# STM32H7P4xx register map
File version: 1.0
Registers are 32-bit, read-write, reset 0x0 unless marked. A register's access mark holds for its fields unless they carry their own. Offsets are from the block's base; [hi:lo] are bit positions; {n}, {i} and the like mark numbered series; 'fields as' and 'values as' point back to an identical list.

## RCC — Reset and clock control (RCC)
Base 0x58024400
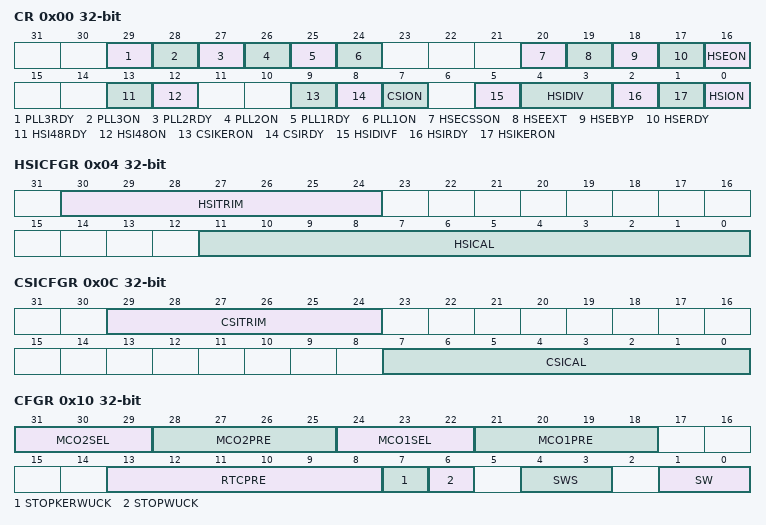
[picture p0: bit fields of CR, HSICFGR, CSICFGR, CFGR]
0x00 CR — RCC source control register
  [29] PLL3RDY — PLL3 clock ready flag
  [28] PLL3ON — PLL3 enable
  [27] PLL2RDY — PLL2 clock ready flag
  [26] PLL2ON — PLL2 enable
  [25] PLL1RDY — PLL1 clock ready flag
  [24] PLL1ON — PLL1 enable
  [20] HSECSSON
  [19] HSEEXT
  [18] HSEBYP — HSE clock bypass
  [17] HSERDY — HSE clock ready flag
  [16] HSEON — HSE clock enable
  [13] HSI48RDY — HSI48 clock ready flag
  [12] HSI48ON — HSI48 clock enable
  [9] CSIKERON — CSI clock enable in Stop mode
  [8] CSIRDY — CSI clock ready flag
  [7] CSION — CSI clock enable
  [5] HSIDIVF — HSI divider flag
  [4:3] HSIDIV — HSI clock divider
  [2] HSIRDY — HSI clock ready flag
  [1] HSIKERON — HSI clock enable in Stop mode
  [0] HSION — HSI clock enable
0x04 HSICFGR — RCC HSI calibration register
  [30:24] HSITRIM — HSI clock trimming
  [11:0] HSICAL — HSI clock calibration
0x08 CRRCR ro — RCC clock recovery RC register
  [9:0] HSI48CAL
0x0C CSICFGR — RCC CSI calibration register
  [29:24] CSITRIM — CSI clock trimming
  [7:0] CSICAL — CSI clock calibration
0x10 CFGR — RCC clock configuration register
  [31:29] MCO2SEL
  [28:25] MCO2PRE — MCO2 prescaler
  [24:22] MCO1SEL
  [21:18] MCO1PRE — MCO1 prescaler
  [13:8] RTCPRE
  [7] STOPKERWUCK
  [6] STOPWUCK
  [4:3] SWS — system clock switch status
  [1:0] SW — system clock switch
0x18 CDCFGR — RCC CPU domain clock configuration register
  [3:0] CPRE — CPU domain core prescaler
0x1C BMCFGR — RCC AHB clock configuration register
  [3:0] BMPRE — Bus matrix clock prescaler
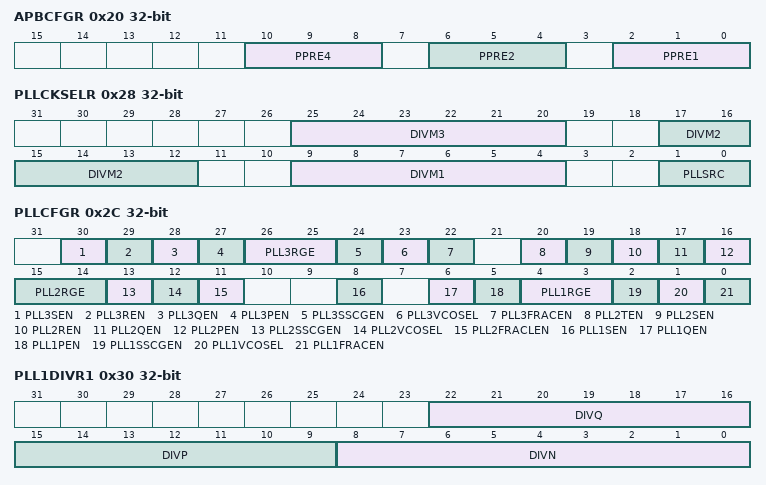
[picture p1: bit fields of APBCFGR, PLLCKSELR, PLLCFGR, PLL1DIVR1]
0x20 APBCFGR — RCC APB clocks configuration register
  [10:8] PPRE4 — CPU domain APB4 prescaler
  [6:4] PPRE2 — CPU domain APB2 prescaler
  [2:0] PPRE1 — CPU domain APB1 prescaler
0x28 PLLCKSELR — RCC PLLs clock source selection register
  [25:20] DIVM3 — prescaler for PLL3
  [17:12] DIVM2 — prescaler for PLL2
  [9:4] DIVM1 — prescaler for PLL1
  [1:0] PLLSRC
0x2C PLLCFGR — RCC PLLs configuration register
  [30] PLL3SEN
  [29] PLL3REN
  [28] PLL3QEN
  [27] PLL3PEN
  [26:25] PLL3RGE — PLL3 input frequency range
  [24] PLL3SSCGEN — PLL3 SSCG enable
  [23] PLL3VCOSEL — PLL3 VCO selection
  [22] PLL3FRACEN — PLL3 fractional latch enable
  [20] PLL2TEN
  [19] PLL2SEN
  [18] PLL2REN
  [17] PLL2QEN
  [16] PLL2PEN
  [15:14] PLL2RGE — PLL2 input frequency range
  [13] PLL2SSCGEN — PLL2 SSCG enable
  [12] PLL2VCOSEL — PLL2 VCO selection
  [11] PLL2FRACLEN — PLL2 fractional latch enable
  [8] PLL1SEN
  [6] PLL1QEN
  [5] PLL1PEN
  [4:3] PLL1RGE — PLL1 input frequency range
  [2] PLL1SSCGEN — PLL1 SSCG enable
  [1] PLL1VCOSEL — PLL1 VCO selection
  [0] PLL1FRACEN — PLL1 fractional latch enable
0x30 PLL1DIVR1 — RCC PLL1 dividers configuration register 1
  [22:16] DIVQ — PLL1 DIVQ division factor
  [15:9] DIVP — PLL1 DIVP division factor
  [8:0] DIVN
{0x2C+8i} PLL{i}FRACR (i=1..3) — RCC PLL{i} fractional divider register
  [15:3] FRACN
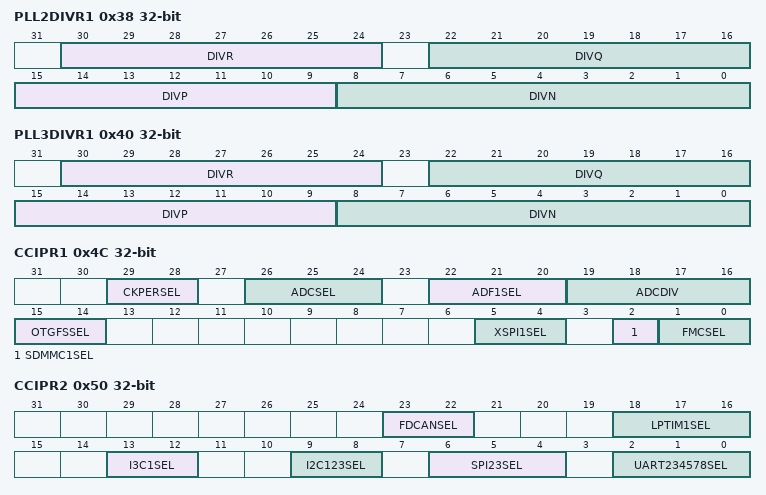
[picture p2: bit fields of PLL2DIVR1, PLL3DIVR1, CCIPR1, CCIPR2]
0x38 PLL2DIVR1 — RCC PLL2 dividers configuration register 1
  [30:24] DIVR — PLL2 DIVR division factor
  [22:16] DIVQ — PLL2 DIVQ division factor
  [15:9] DIVP — PLL2 DIVP division factor
  [8:0] DIVN
0x40 PLL3DIVR1 — RCC PLL3 dividers configuration register 1
  [30:24] DIVR — PLL3 DIVR division factor
  [22:16] DIVQ — PLL3 DIVQ division factor
  [15:9] DIVP — PLL3 DIVP division factor
  [8:0] DIVN
0x4C CCIPR1 — RCC peripheral kernel clock selection register 1
  [29:28] CKPERSEL — per_ck clock source selection
  [26:24] ADCSEL
  [22:20] ADF1SEL
  [19:16] ADCDIV
  [15:14] OTGFSSEL
  [5:4] XSPI1SEL
  [2] SDMMC1SEL
  [1:0] FMCSEL
0x50 CCIPR2 — RCC peripheral kernel clock selection register 2
  [23:22] FDCANSEL, [18:16] LPTIM1SEL, [13:12] I3C1SEL, [9:8] I2C123SEL, [6:4] SPI23SEL, [2:0] UART234578SEL
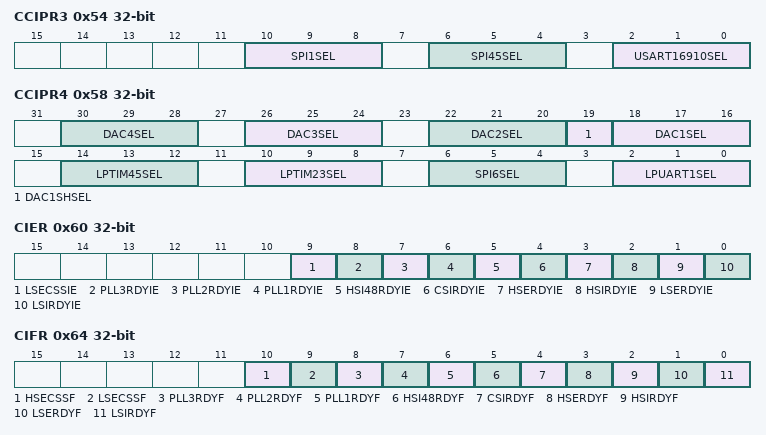
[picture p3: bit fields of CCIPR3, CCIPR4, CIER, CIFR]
0x54 CCIPR3 — RCC peripheral kernel clock selection register 3
  [10:8] SPI1SEL, [6:4] SPI45SEL, [2:0] USART16910SEL
0x58 CCIPR4 — RCC peripheral kernel clock selection register 4
  [4n+14:4n+12] DAC{n}SEL (n=1..4)
  [19] DAC1SHSEL — DAC1 hold clock selection
  [14:12] LPTIM45SEL
  [10:8] LPTIM23SEL
  [6:4] SPI6SEL
  [2:0] LPUART1SEL
0x60 CIER — RCC clock source interrupt enable register
  [9] LSECSSIE
  [8] PLL3RDYIE — PLL3 ready interrupt enable
  [7] PLL2RDYIE — PLL2 ready interrupt enable
  [6] PLL1RDYIE — PLL1 ready interrupt enable
  [5] HSI48RDYIE — HSI48 ready interrupt enable
  [4] CSIRDYIE — CSI ready interrupt enable
  [3] HSERDYIE — HSE ready interrupt enable
  [2] HSIRDYIE — HSI ready interrupt enable
  [1] LSERDYIE — LSE ready interrupt enable
  [0] LSIRDYIE — LSI ready interrupt enable
0x64 CIFR ro — RCC clock source interrupt flag register
  [10] HSECSSF
  [9] LSECSSF
  [8] PLL3RDYF — PLL3 ready interrupt flag
  [7] PLL2RDYF — PLL2 ready interrupt flag
  [6] PLL1RDYF — PLL1 ready interrupt flag
  [5] HSI48RDYF — HSI48 ready interrupt flag
  [4] CSIRDYF — CSI ready interrupt flag
  [3] HSERDYF — HSE ready interrupt flag
  [2] HSIRDYF — HSI ready interrupt flag
  [1] LSERDYF — LSE ready interrupt flag
  [0] LSIRDYF — LSI ready interrupt flag
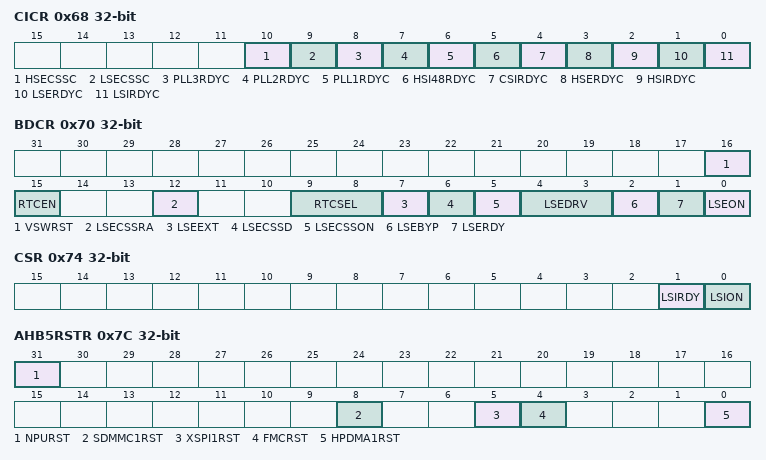
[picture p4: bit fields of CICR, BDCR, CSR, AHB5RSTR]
0x68 CICR — RCC clock source interrupt clear register
  [10] HSECSSC
  [9] LSECSSC
  [8] PLL3RDYC — PLL3 ready interrupt clear
  [7] PLL2RDYC — PLL2 ready interrupt clear
  [6] PLL1RDYC — PLL1 ready interrupt clear
  [5] HSI48RDYC — HSI48 ready interrupt clear
  [4] CSIRDYC — CSI ready interrupt clear
  [3] HSERDYC — HSE ready interrupt clear
  [2] HSIRDYC — HSI ready interrupt clear
  [1] LSERDYC — LSE ready interrupt clear
  [0] LSIRDYC — LSI ready interrupt clear
0x70 BDCR — RCC Backup domain control register
  [16] VSWRST — VSwitch domain software reset
  [15] RTCEN — RTC clock enable
  [12] LSECSSRA — Re-Arm the LSECSS function
  [9:8] RTCSEL — RTC clock source selection
  [7] LSEEXT
  [6] LSECSSD
  [5] LSECSSON
  [4:3] LSEDRV
  [2] LSEBYP — LSE oscillator bypass
  [1] LSERDY — LSE oscillator ready
  [0] LSEON — LSE oscillator enabled
0x74 CSR — RCC clock control and status register
  [1] LSIRDY — LSI oscillator ready
  [0] LSION — LSI oscillator enable
0x7C AHB5RSTR — RCC AHB5 peripheral reset register
  [31] NPURST — NPU block reset
  [8] SDMMC1RST
  [5] XSPI1RST — XSPI1 and MCE1 blocks reset
  [4] FMCRST — FMC and MCE3 blocks reset
  [0] HPDMA1RST — HPDMA1 block reset
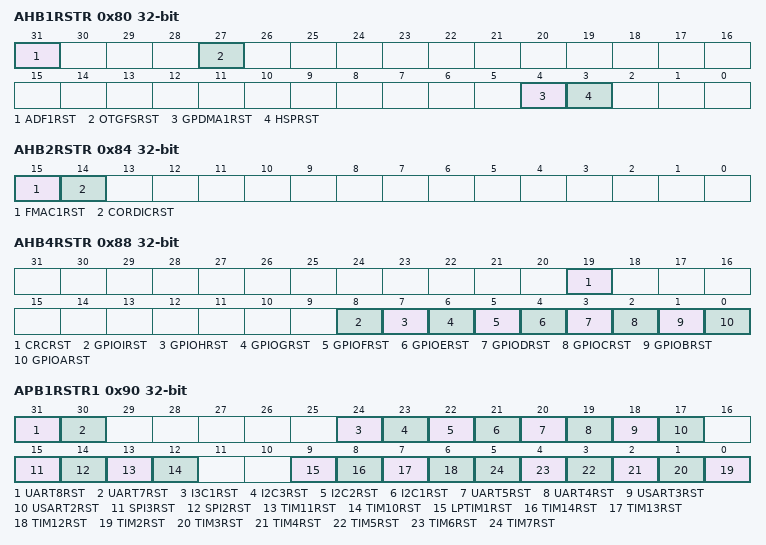
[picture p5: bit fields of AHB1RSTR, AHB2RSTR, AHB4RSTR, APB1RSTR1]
0x80 AHB1RSTR — RCC AHB1 peripheral reset register
  [31] ADF1RST — ADF block reset
  [27] OTGFSRST — OTGFS block reset
  [4] GPDMA1RST — GPDMA1 blocks reset
  [3] HSPRST — HSP block reset
0x84 AHB2RSTR — RCC AHB2 peripheral reset register
  [15] FMAC1RST — FMAC reset
  [14] CORDICRST — CORDIC reset
0x88 AHB4RSTR — RCC AHB4 peripheral reset register
  [19] CRCRST — CRC block reset
  [8] GPIOIRST — GPIOI block reset
  [7] GPIOHRST — GPIOH block reset
  [6] GPIOGRST — GPIOG block reset
  [5] GPIOFRST — GPIOF block reset
  [4] GPIOERST — GPIOE block reset
  [3] GPIODRST — GPIOD block reset
  [2] GPIOCRST — GPIOC block reset
  [1] GPIOBRST — GPIOB block reset
  [0] GPIOARST — GPIOA block reset
0x90 APB1RSTR1 — RCC APB1 peripheral reset register 1
  [31] UART8RST — UART8 block reset
  [30] UART7RST — UART7 block reset
  [24] I3C1RST — I3C1 block reset
  [23] I2C3RST — I2C3 block reset
  [22] I2C2RST — I2C2 block reset
  [21] I2C1RST — I2C1/I3C1 block reset
  [20] UART5RST — UART5 block reset
  [19] UART4RST — UART4 block reset
  [18] USART3RST — USART3 block reset
  [17] USART2RST — USART2 block reset
  [15] SPI3RST — SPI2S3 block reset
  [14] SPI2RST — SPI2S2 block reset
  [13] TIM11RST — TIM11 block reset
  [12] TIM10RST — TIM10 block reset
  [9] LPTIM1RST — LPTIM1 block reset
  [8] TIM14RST — TIM14 block reset
  [7] TIM13RST — TIM13 block reset
  [6] TIM12RST — TIM12 block reset
  [n-2] TIM{n}RST (n=2..7) — TIM{n} block reset
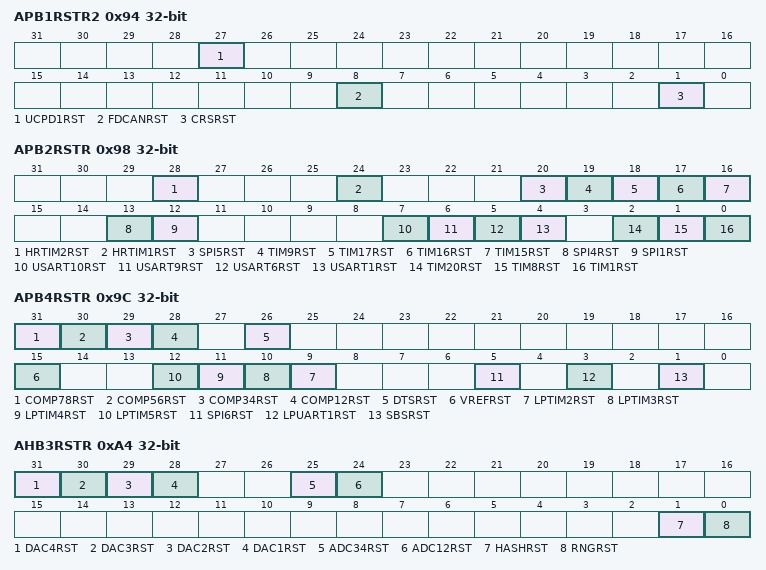
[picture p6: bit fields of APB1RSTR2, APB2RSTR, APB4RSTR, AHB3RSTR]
0x94 APB1RSTR2 — RCC APB1 peripheral reset register 2
  [27] UCPD1RST — UCPD block reset
  [8] FDCANRST — FDCAN block reset
  [1] CRSRST — clock recovery system reset
0x98 APB2RSTR — RCC APB2 peripheral reset register
  [28] HRTIM2RST — HRTIM2 block reset
  [24] HRTIM1RST — HRTIM1 block reset
  [20] SPI5RST — SPI5 block reset
  [19] TIM9RST — TIM9 block reset
  [18] TIM17RST — TIM17 block reset
  [17] TIM16RST — TIM16 block reset
  [16] TIM15RST — TIM15 block reset
  [13] SPI4RST — SPI4 block reset
  [12] SPI1RST — SPI2S1 block reset
  [7] USART10RST — USART10 block reset
  [6] USART9RST — USART9 block reset
  [5] USART6RST — USART6 block reset
  [4] USART1RST — USART1 block reset
  [2] TIM20RST — TIM20 block reset
  [1] TIM8RST — TIM8 block reset
  [0] TIM1RST — TIM1 block reset
0x9C APB4RSTR — RCC APB4 peripheral reset register
  [31] COMP78RST — COMP78 block reset
  [30] COMP56RST — COMP56 block reset
  [29] COMP34RST — COMP34 block reset
  [28] COMP12RST — COMP512 block reset
  [26] DTSRST — DTS block reset
  [15] VREFRST — VREF block reset
  [n+7] LPTIM{n}RST (n=2..5) — LPTIM{n} block reset
  [5] SPI6RST — SPI/I2S6 block reset
  [3] LPUART1RST — LPUART1 block reset
  [1] SBSRST — SBS block reset
0xA4 AHB3RSTR — RCC AHB3 peripheral reset register
  [31] DAC4RST — DAC4block reset
  [30] DAC3RST — DAC3 block reset
  [29] DAC2RST — DAC2 block reset
  [28] DAC1RST — DAC1 block reset
  [25] ADC34RST — ADC34 block reset
  [24] ADC12RST — ADC12 block reset
  [1] HASHRST — HASH block reset
  [0] RNGRST
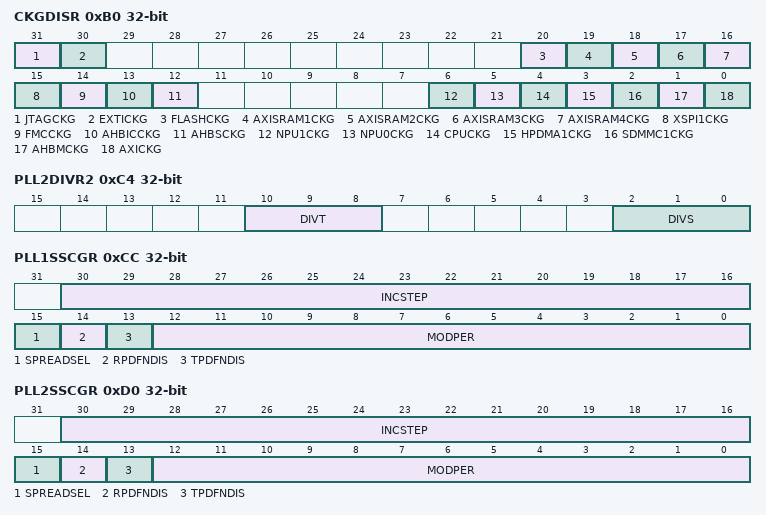
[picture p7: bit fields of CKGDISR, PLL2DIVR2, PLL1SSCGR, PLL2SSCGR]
0xB0 CKGDISR — RCC AXI clocks gating disable register
  [31] JTAGCKG
  [30] EXTICKG — EXTI clock gating disable
  [20] FLASHCKG
  [20-n] AXISRAM{n}CKG (n=1..4)
  [15] XSPI1CKG
  [14] FMCCKG
  [13] AHBICCKG
  [12] AHBSCKG
  [6] NPU1CKG
  [5] NPU0CKG
  [4] CPUCKG
  [3] HPDMA1CKG
  [2] SDMMC1CKG
  [1] AHBMCKG
  [0] AXICKG
0xC0 PLL1DIVR2 — RCC PLL1 dividers configuration register 2
  [2:0] DIVS — PLL1 DIVS division factor
0xC4 PLL2DIVR2 — RCC PLL2 dividers configuration register 2
  [10:8] DIVT — PLL2 DIVT division factor
  [2:0] DIVS — PLL2 DIVS division factor
0xC8 PLL3DIVR2 — RCC PLL3 dividers configuration register 2
  [2:0] DIVS — PLL3 DIVS division factor
0xCC PLL1SSCGR — RCC PLL1 Spread Spectrum Clock Generator register
  [30:16] INCSTEP, [15] SPREADSEL, [14] RPDFNDIS, [13] TPDFNDIS, [12:0] MODPER
0xD0 PLL2SSCGR — RCC PLL2 spread spectrum clock generator register
  fields as PLL1SSCGR
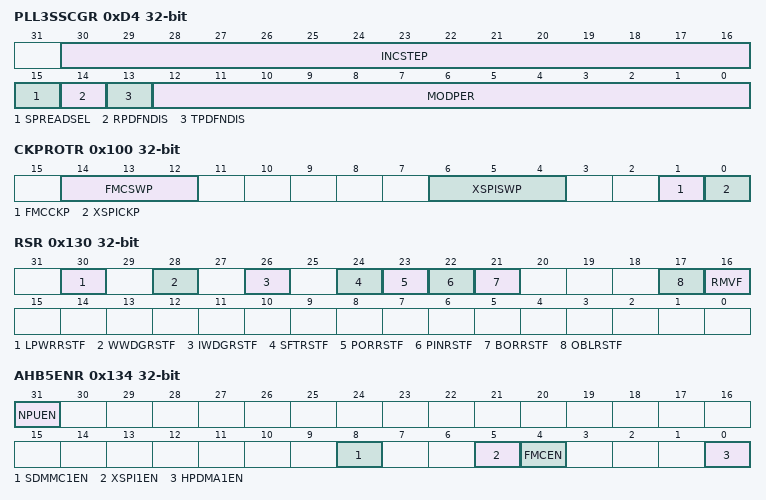
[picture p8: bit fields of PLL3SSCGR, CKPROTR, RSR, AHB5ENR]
0xD4 PLL3SSCGR — RCC PLL3 spread spectrum clock generator register
  fields as PLL1SSCGR
0x100 CKPROTR — RCC clock protection register
  [14:12] FMCSWP
  [6:4] XSPISWP
  [1] FMCCKP — FMC clock protection
  [0] XSPICKP — XSPI clock protection
0x130 RSR — RCC Reset status register
  [30] LPWRRSTF
  [28] WWDGRSTF — window watchdog reset flag
  [26] IWDGRSTF
  [24] SFTRSTF
  [23] PORRSTF — POR/PDR reset flag
  [22] PINRSTF — pin reset flag (NRST)
  [21] BORRSTF — BOR reset flag
  [17] OBLRSTF
  [16] RMVF — remove reset flags
0x134 AHB5ENR — RCC AHB5 clock enable register
  [31] NPUEN — NPU clock enable
  [8] SDMMC1EN
  [5] XSPI1EN
  [4] FMCEN — FMC peripheral clocks enable
  [0] HPDMA1EN
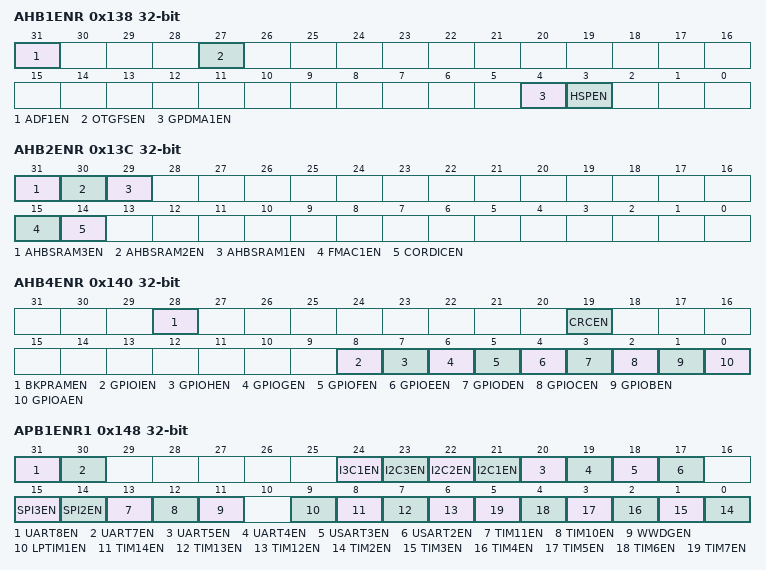
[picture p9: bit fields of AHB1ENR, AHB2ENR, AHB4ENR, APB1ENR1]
0x138 AHB1ENR — RCC AHB1 clock enable register
  [31] ADF1EN — ADF clocks enable
  [27] OTGFSEN
  [4] GPDMA1EN — GPDMA1 clock enable
  [3] HSPEN — HSP clock enable
0x13C AHB2ENR — RCC AHB2 clock enable register
  [31] AHBSRAM3EN — AHBSRAM3 clock enable
  [30] AHBSRAM2EN — AHBSRAM2 clock enable
  [29] AHBSRAM1EN — AHBSRAM1 clock enable
  [15] FMAC1EN — FMAC clock enable
  [14] CORDICEN — CORDIC clock enable
0x140 AHB4ENR — RCC AHB4 clock enable register
  [28] BKPRAMEN — Backup RAM clock enable
  [19] CRCEN — CRC clock enable
  [8] GPIOIEN — GPIOI peripheral clock enable
  [7] GPIOHEN — GPIOH peripheral clock enable
  [6] GPIOGEN — GPIOG peripheral clock enable
  [5] GPIOFEN — GPIOF peripheral clock enable
  [4] GPIOEEN — GPIOE peripheral clock enable
  [3] GPIODEN — GPIOD peripheral clock enable
  [2] GPIOCEN — GPIOC peripheral clock enable
  [1] GPIOBEN — GPIOB peripheral clock enable
  [0] GPIOAEN — GPIOA peripheral clock enable
0x148 APB1ENR1 — RCC APB1 clock enable register 1
  [31] UART8EN
  [30] UART7EN
  [24] I3C1EN — I3C1 peripheral clocks enable
  [23] I2C3EN — I2C3 peripheral clocks enable
  [22] I2C2EN — I2C2 peripheral clocks enable
  [21] I2C1EN — I2C1 peripheral clocks enable
  [20] UART5EN
  [19] UART4EN
  [18] USART3EN
  [17] USART2EN
  [15] SPI3EN — SPI3 peripheral clocks enable
  [14] SPI2EN — SPI2 peripheral clocks enable
  [13] TIM11EN — TIM11 peripheral clock enable
  [12] TIM10EN — TIM10 peripheral clock enable
  [11] WWDGEN — WWDG clock enable
  [9] LPTIM1EN
  [8] TIM14EN — TIM14 peripheral clock enable
  [7] TIM13EN — TIM13 peripheral clock enable
  [6] TIM12EN — TIM12 peripheral clock enable
  [n-2] TIM{n}EN (n=2..7) — TIM{n} peripheral clock enable
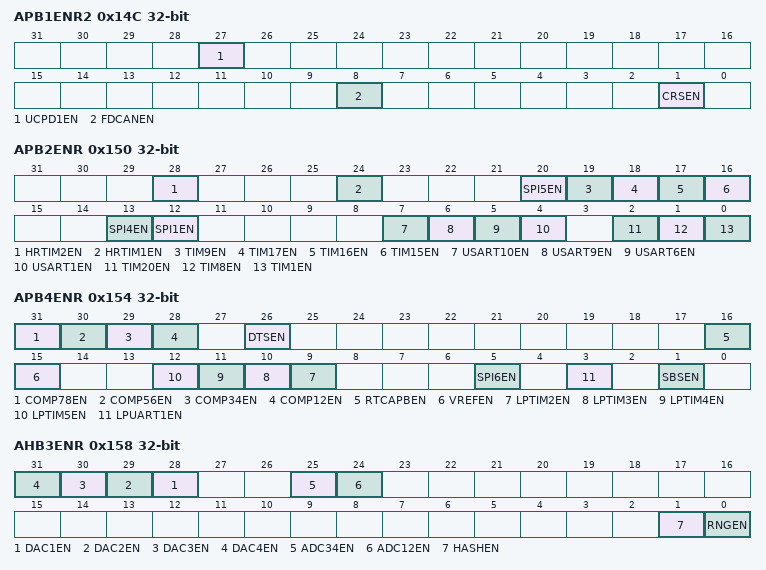
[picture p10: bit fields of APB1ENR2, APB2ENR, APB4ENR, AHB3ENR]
0x14C APB1ENR2 — RCC APB1 clock enable register 2
  [27] UCPD1EN — UCPD peripheral clock enable
  [8] FDCANEN — FDCAN peripheral clock enable
  [1] CRSEN
0x150 APB2ENR — RCC APB2 clock enable register
  [28] HRTIM2EN
  [24] HRTIM1EN
  [20] SPI5EN — SPI5 peripheral clocks enable
  [19] TIM9EN — TIM9 peripheral clock enable
  [18] TIM17EN — TIM17 peripheral clock enable
  [17] TIM16EN — TIM16 peripheral clock enable
  [16] TIM15EN — TIM15 peripheral clock enable
  [13] SPI4EN — SPI4 Peripheral Clocks Enable
  [12] SPI1EN
  [7] USART10EN
  [6] USART9EN
  [5] USART6EN
  [4] USART1EN
  [2] TIM20EN — TIM20 peripheral clock enable
  [1] TIM8EN — TIM8 peripheral clock enable
  [0] TIM1EN — TIM1 peripheral clock enable
0x154 APB4ENR — RCC APB4 clock enable register
  [31] COMP78EN
  [30] COMP56EN
  [29] COMP34EN
  [28] COMP12EN
  [26] DTSEN
  [16] RTCAPBEN — RTC APB clock enable
  [15] VREFEN — VREF peripheral clock enable
  [n+7] LPTIM{n}EN (n=2..5)
  [5] SPI6EN
  [3] LPUART1EN
  [1] SBSEN — SBS peripheral clock enable
0x158 AHB3ENR — RCC AHB3 clock enable register
  [n+27] DAC{n}EN (n=1..4) — DAC{n} peripheral clock enable
  [25] ADC34EN — ADC34 peripheral clock enable
  [24] ADC12EN — ADC12 peripheral clock enable
  [1] HASHEN — HASH peripheral clock enable
  [0] RNGEN — RNG peripheral clocks enable
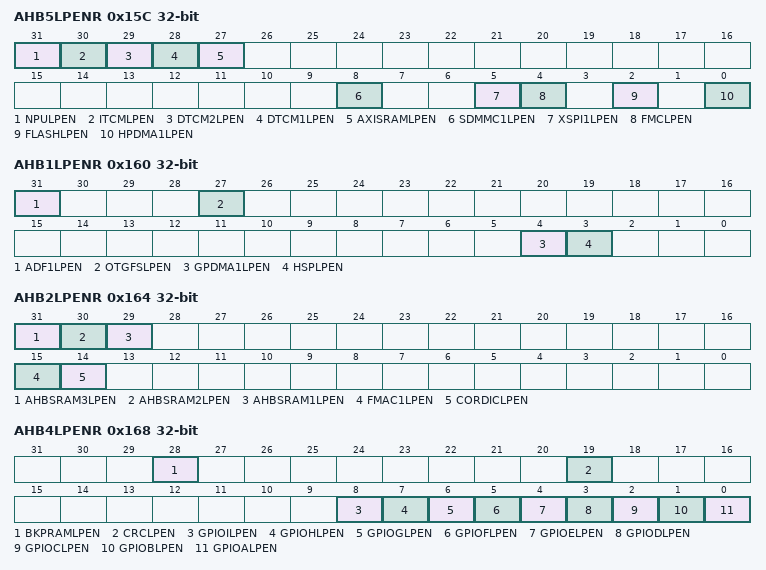
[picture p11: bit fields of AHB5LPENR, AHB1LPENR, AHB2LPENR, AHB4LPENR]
0x15C AHB5LPENR — RCC AHB5 low-power clock enable register
  [31] NPULPEN, [30] ITCMLPEN, [29] DTCM2LPEN, [28] DTCM1LPEN, [27] AXISRAMLPEN, [8] SDMMC1LPEN, [5] XSPI1LPEN, [4] FMCLPEN, [2] FLASHLPEN, [0] HPDMA1LPEN
0x160 AHB1LPENR — RCC AHB1 low-power clock enable register
  [31] ADF1LPEN, [27] OTGFSLPEN, [4] GPDMA1LPEN, [3] HSPLPEN
0x164 AHB2LPENR — RCC AHB2 low-power clock enable register
  [31] AHBSRAM3LPEN, [30] AHBSRAM2LPEN, [29] AHBSRAM1LPEN, [15] FMAC1LPEN, [14] CORDICLPEN
0x168 AHB4LPENR — RCC AHB4 low-power clock enable register
  [28] BKPRAMLPEN, [19] CRCLPEN, [8] GPIOILPEN, [7] GPIOHLPEN, [6] GPIOGLPEN, [5] GPIOFLPEN, [4] GPIOELPEN, [3] GPIODLPEN, [2] GPIOCLPEN, [1] GPIOBLPEN, [0] GPIOALPEN
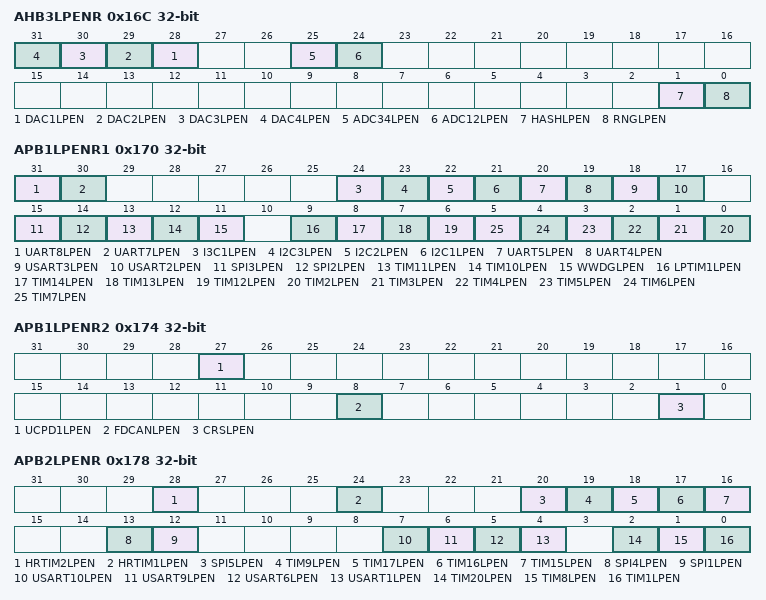
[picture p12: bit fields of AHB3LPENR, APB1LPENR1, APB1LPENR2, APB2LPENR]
0x16C AHB3LPENR — RCC AHB3 low-power clock enable register
  [n+27] DAC{n}LPEN (n=1..4), [25] ADC34LPEN, [24] ADC12LPEN, [1] HASHLPEN, [0] RNGLPEN
0x170 APB1LPENR1 — RCC APB1 low-power clock enable register 1
  [31] UART8LPEN, [30] UART7LPEN, [24] I3C1LPEN, [23] I2C3LPEN, [22] I2C2LPEN, [21] I2C1LPEN, [20] UART5LPEN, [19] UART4LPEN, [18] USART3LPEN, [17] USART2LPEN, [15] SPI3LPEN, [14] SPI2LPEN, [13] TIM11LPEN, [12] TIM10LPEN, [11] WWDGLPEN, [9] LPTIM1LPEN, [8] TIM14LPEN, [7] TIM13LPEN, [6] TIM12LPEN, [n-2] TIM{n}LPEN (n=2..7)
0x174 APB1LPENR2 — RCC APB1 low-power clock enable register 2
  [27] UCPD1LPEN, [8] FDCANLPEN, [1] CRSLPEN
0x178 APB2LPENR — RCC APB2 low-power clock enable register
  [28] HRTIM2LPEN, [24] HRTIM1LPEN, [20] SPI5LPEN, [19] TIM9LPEN, [18] TIM17LPEN, [17] TIM16LPEN, [16] TIM15LPEN, [13] SPI4LPEN, [12] SPI1LPEN, [7] USART10LPEN, [6] USART9LPEN, [5] USART6LPEN, [4] USART1LPEN, [2] TIM20LPEN, [1] TIM8LPEN, [0] TIM1LPEN
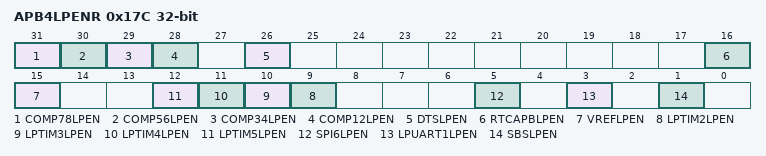
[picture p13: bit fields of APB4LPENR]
0x17C APB4LPENR — RCC APB4 low-power clock enable register
  [31] COMP78LPEN, [30] COMP56LPEN, [29] COMP34LPEN, [28] COMP12LPEN, [26] DTSLPEN, [16] RTCAPBLPEN, [15] VREFLPEN, [n+7] LPTIM{n}LPEN (n=2..5), [5] SPI6LPEN, [3] LPUART1LPEN, [1] SBSLPEN
